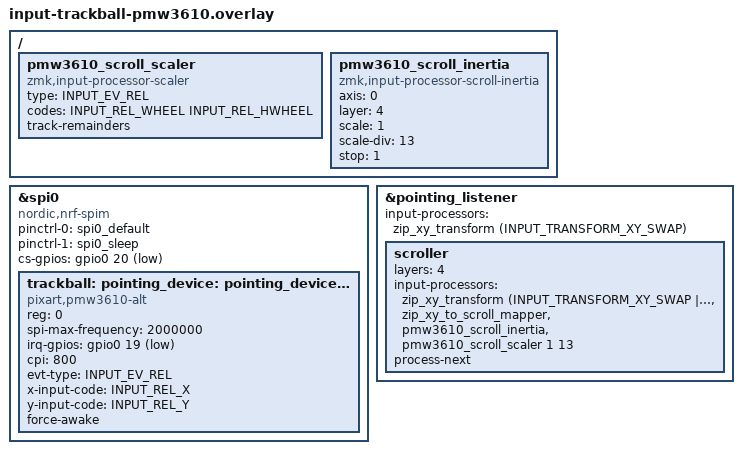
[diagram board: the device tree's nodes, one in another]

#include <dt-bindings/zmk/input_transform.h>

/ {
    pmw3610_scroll_scaler: pmw3610_scroll_scaler {
        compatible = "zmk,input-processor-scaler";
        #input-processor-cells = <2>;
        type = <INPUT_EV_REL>;
        codes = <INPUT_REL_WHEEL INPUT_REL_HWHEEL>;
        track-remainders;
    };

    pmw3610_scroll_inertia: pmw3610_scroll_inertia {
        compatible = "zmk,input-processor-scroll-inertia";
        #input-processor-cells = <0>;

        /* axis = 0: both axes, matching the free vertical/horizontal
         * scroll already produced by zip_xy_to_scroll_mapper below. */
        axis = <0>;
        layer = <4>;

        /* Must match the &pmw3610_scroll_scaler args downstream. */
        scale = <1>;
        scale-div = <13>;

        /* Lowered from the default (7) to match our small scale/scale-div
         * ratio: output frequency at cutoff = stop * scale * 125 / scale-div. */
        stop = <1>;
    };
};

&spi0 {
    status = "okay";
    compatible = "nordic,nrf-spim";
    pinctrl-0 = <&spi0_default>;
    pinctrl-1 = <&spi0_sleep>;
    pinctrl-names = "default", "sleep";
    cs-gpios = <&gpio0 20 GPIO_ACTIVE_LOW>;

    trackball: pointing_device: pointing_device@0 {
        status = "okay";
        compatible = "pixart,pmw3610-alt";
        reg = <0>;
        spi-max-frequency = <2000000>;
        irq-gpios = <&gpio0 19 (GPIO_ACTIVE_LOW | GPIO_PULL_UP)>;
        cpi = <800>;
        evt-type = <INPUT_EV_REL>;
        x-input-code = <INPUT_REL_X>;
        y-input-code = <INPUT_REL_Y>;
        force-awake;
    };
};

&pointing_listener {
    input-processors =
        <&zip_xy_transform (INPUT_TRANSFORM_XY_SWAP)>;

    scroller {
        layers = <4>;
        input-processors =
            <&zip_xy_transform (INPUT_TRANSFORM_XY_SWAP | INPUT_TRANSFORM_Y_INVERT)>,
            <&zip_xy_to_scroll_mapper>,
            <&pmw3610_scroll_inertia>,
            <&pmw3610_scroll_scaler 1 13>;
        process-next;
    };
};
